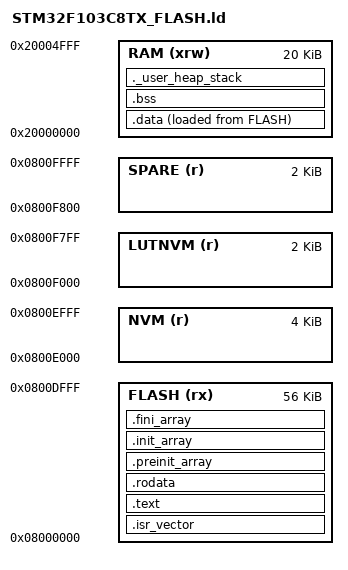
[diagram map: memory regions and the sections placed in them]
/*
******************************************************************************
**
** @file        : LinkerScript.ld
**
** @author      : Auto-generated by STM32CubeIDE
**
** @brief       : Linker script for STM32F103C8Tx Device from STM32F1 series
**                      64KBytes FLASH
**                      20KBytes RAM
**
**                Set heap size, stack size and stack location according
**                to application requirements.
**
**                Set memory bank area and size if external memory is used
**
**  Target      : STMicroelectronics STM32
**
**  Distribution: The file is distributed as is, without any warranty
**                of any kind.
**
******************************************************************************
** @attention
**
** Copyright (c) 2026 STMicroelectronics.
** All rights reserved.
**
** This software is licensed under terms that can be found in the LICENSE file
** in the root directory of this software component.
** If no LICENSE file comes with this software, it is provided AS-IS.
**
******************************************************************************
*/

/* Entry Point */
ENTRY(Reset_Handler)

/* Highest address of the user mode stack */
_estack = ORIGIN(RAM) + LENGTH(RAM); /* end of "RAM" Ram type memory */

_Min_Heap_Size = 0x200; /* required amount of heap */
_Min_Stack_Size = 0x400; /* required amount of stack */

/* Memories definition */
/* [EN] v1.14 (user order 2026-09-25): the TOP two 1 KiB pages (0x0800F800,
   0x0800FC00) are reserved for the ping-pong parameter-persistence records
   (esp_link_nvm.c), so application FLASH shrinks 64K -> 62K and the linker
   itself errors if the image ever tries to collide with the records.
   [FA] v1.14 (دستور کاربر ۲۰۲۶-۰۹-۲۵): دو صفحهٔ ۱KB بالایی (0x0800F800 و
   0x0800FC00) برای رکوردهای پینگ‌پنگ ماندگاری پارامترها (esp_link_nvm.c)
   رزرو شده‌اند؛ فلش برنامه از 64K به 62K کوچک شد تا خود لینکر اگر روزی
   تصویر برنامه با رکوردها تصادم کند خطا بدهد. */
/* [EN] v1.66 (user order 2026-10-05: push the calibration table straight into
   the micro, on a storage path SEPARATE from the other variables): two MORE
   1 KiB pages (0x0800F000, 0x0800F400) are reserved, directly below the
   parameter records, for the bench-LUT ping-pong block (cal_lut.c).
   Application FLASH therefore shrinks 62K -> 60K. The image is ~40 KB, so the
   room exists; and because the two blocks are separate, a LUT push can never
   damage a parameter record (that is what the extra 1 KiB buys).
   [FA] v1.66 (دستور کاربر ۲۰۲۶-۱۰-۰۵: جدول مستقیم به میکرو، روی مسیر ذخیره‌سازی
   «جدا» از بقیهٔ متغیرها): دو صفحهٔ ۱KB دیگر (0x0800F000 و 0x0800F400) درست
   زیر رکوردهای پارامتر برای بلوک پینگ‌پنگ جدول بنچ رزرو شد، پس فلش برنامه از
   62K به 60K کوچک می‌شود. تصویر برنامه ~۴۰KB است، پس جا هست؛ و چون دو بلوک
   جدا هستند، ارسال جدول هرگز رکورد پارامترها را خراب نمی‌کند. */
/* [EN] v1.80 (user order: scenario 6 gets its own lamp/buzzer ids 128..131):
   the parameter record outgrew a single 1 KiB page, so each ping-pong bank is
   two pages now and the whole record block moved DOWN to 0x0800E000..0x0800EFFF
   (4 KiB, two 2 KiB banks). Application FLASH shrinks 60K -> 56K; the image is
   ~40 KB, so the room exists. The old record pages at 0x0800F800..0x0800FFFF
   are kept out of FLASH as SPARE rather than handed back to the application:
   a board upgraded in the field still has stale records there, and reusing
   those 2 KiB for code would be the one change that could not be undone.
   [FA] رکورد پارامترها از یک صفحهٔ ۱KB بزرگ‌تر شد؛ هر بانک دو صفحه شد و کل
   بلوک به 0x0800E000 منتقل شد (۴KB). فلش برنامه از 60K به 56K می‌رسد و دو
   صفحهٔ قدیمی بالا به‌عنوان یدک کنار گذاشته می‌شود. */
MEMORY
{
  RAM    (xrw)    : ORIGIN = 0x20000000,   LENGTH = 20K
  FLASH    (rx)    : ORIGIN = 0x8000000,   LENGTH = 56K
  NVM      (r)     : ORIGIN = 0x800E000,   LENGTH = 4K
  LUTNVM   (r)     : ORIGIN = 0x800F000,   LENGTH = 2K
  SPARE    (r)     : ORIGIN = 0x800F800,   LENGTH = 2K
}

/* Sections */
SECTIONS
{

  /* The startup code into "FLASH" Rom type memory */
  .isr_vector :
  {
    . = ALIGN(4);
    KEEP(*(.isr_vector)) /* Startup code */
    . = ALIGN(4);
  } >FLASH

  /* The program code and other data into "FLASH" Rom type memory */
  .text :
  {
    . = ALIGN(4);
    *(.text)           /* .text sections (code) */
    *(.text*)          /* .text* sections (code) */
    *(.glue_7)         /* glue arm to thumb code */
    *(.glue_7t)        /* glue thumb to arm code */
    *(.eh_frame)

    KEEP (*(.init))
    KEEP (*(.fini))

    . = ALIGN(4);
    _etext = .;        /* define a global symbols at end of code */
  } >FLASH

  /* Constant data into "FLASH" Rom type memory */
  .rodata :
  {
    . = ALIGN(4);
    *(.rodata)         /* .rodata sections (constants, strings, etc.) */
    *(.rodata*)        /* .rodata* sections (constants, strings, etc.) */
    . = ALIGN(4);
  } >FLASH

  /* [EN] Flash diet 2026-09-27: discard C++ unwinding tables. This is a
     pure-C bare-metal image (no exceptions); keeping them costs ~6.4 KiB
     of FLASH whenever --gc-sections is off, and they are dead weight even
     when it is on. Nothing references __exidx_start/end.
     [FA] رژیم فلش: جدول‌های unwind سی++ دور ریخته می‌شود (کد خالص C است؛
     بدون gc حدود ۶٫۴KB فلش می‌بلعید). */
  /DISCARD/ :
  {
    *(.ARM.extab* .gnu.linkonce.armextab.*)
    *(.ARM.exidx*)
  }

  .preinit_array (READONLY) : /* The "READONLY" keyword is only supported in GCC11 and later, remove it if using GCC10 or earlier. */
  {
    . = ALIGN(4);
    PROVIDE_HIDDEN (__preinit_array_start = .);
    KEEP (*(.preinit_array*))
    PROVIDE_HIDDEN (__preinit_array_end = .);
    . = ALIGN(4);
  } >FLASH

  .init_array (READONLY) : /* The "READONLY" keyword is only supported in GCC11 and later, remove it if using GCC10 or earlier. */
  {
    . = ALIGN(4);
    PROVIDE_HIDDEN (__init_array_start = .);
    KEEP (*(SORT(.init_array.*)))
    KEEP (*(.init_array*))
    PROVIDE_HIDDEN (__init_array_end = .);
    . = ALIGN(4);
  } >FLASH

  .fini_array (READONLY) : /* The "READONLY" keyword is only supported in GCC11 and later, remove it if using GCC10 or earlier. */
  {
    . = ALIGN(4);
    PROVIDE_HIDDEN (__fini_array_start = .);
    KEEP (*(SORT(.fini_array.*)))
    KEEP (*(.fini_array*))
    PROVIDE_HIDDEN (__fini_array_end = .);
    . = ALIGN(4);
  } >FLASH

  /* Used by the startup to initialize data */
  _sidata = LOADADDR(.data);

  /* Initialized data sections into "RAM" Ram type memory */
  .data :
  {
    . = ALIGN(4);
    _sdata = .;        /* create a global symbol at data start */
    *(.data)           /* .data sections */
    *(.data*)          /* .data* sections */
    *(.RamFunc)        /* .RamFunc sections */
    *(.RamFunc*)       /* .RamFunc* sections */

    . = ALIGN(4);
    _edata = .;        /* define a global symbol at data end */

  } >RAM AT> FLASH

  /* Uninitialized data section into "RAM" Ram type memory */
  . = ALIGN(4);
  .bss :
  {
    /* This is used by the startup in order to initialize the .bss section */
    _sbss = .;         /* define a global symbol at bss start */
    __bss_start__ = _sbss;
    *(.bss)
    *(.bss*)
    *(COMMON)

    . = ALIGN(4);
    _ebss = .;         /* define a global symbol at bss end */
    __bss_end__ = _ebss;
  } >RAM

  /* User_heap_stack section, used to check that there is enough "RAM" Ram  type memory left */
  ._user_heap_stack :
  {
    . = ALIGN(8);
    PROVIDE ( end = . );
    PROVIDE ( _end = . );
    . = . + _Min_Heap_Size;
    . = . + _Min_Stack_Size;
    . = ALIGN(8);
  } >RAM

  /* Remove information from the compiler libraries */
  /DISCARD/ :
  {
    libc.a ( * )
    libm.a ( * )
    libgcc.a ( * )
  }

  .ARM.attributes 0 : { *(.ARM.attributes) }
}
